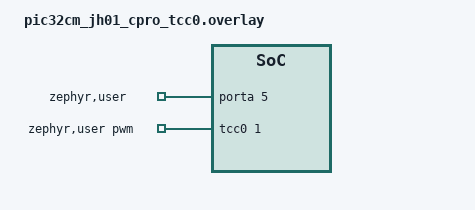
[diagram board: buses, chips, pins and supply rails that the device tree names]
/*
 * SPDX-FileCopyrightText: Copyright 2026 Microchip Technology Inc.
 * SPDX-License-Identifier: Apache-2.0
 */

/* connect PA04 to PA05 */

#define PWM_NODE    tcc0
#define PWM_PINCTRL tcc0_pwm_default
#define PWM_COMPAT "microchip,tcc-g1-pwm"
#include "mchp_pwm_loopback_support.dtsi"

/ {
	zephyr,user {
		pwms = <&tcc0 1 PWM_MSEC(20) 0>;
		gpios = <&porta 5 GPIO_ACTIVE_HIGH>;
	};
};

&porta {
	status = "okay";
};

&pinctrl {
	tcc0_pwm_default: tcc0_pwm_default {
		group1 {
			pinmux = <PA4E_TCC0_WO0>;
		};
	};
};
